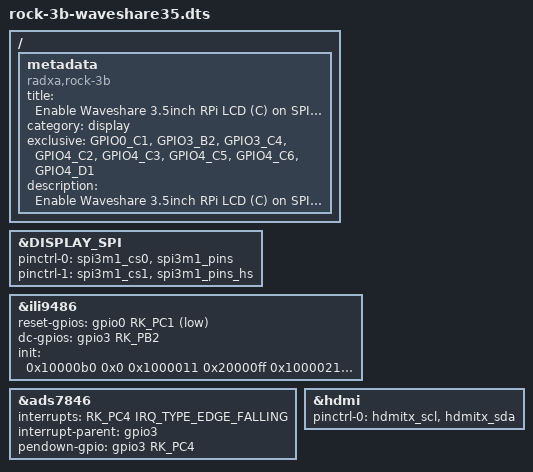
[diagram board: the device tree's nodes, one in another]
#define DISPLAY_SPI spi3
#include "waveshare35-lcd.dtsi"

/ {
	metadata {
		title = "Enable Waveshare 3.5inch RPi LCD (C) on SPI3-M1";
		compatible = "radxa,rock-3b";
		category = "display";
		exclusive = "GPIO0_C1", "GPIO3_B2", "GPIO3_C4", "GPIO4_C2", "GPIO4_C3", "GPIO4_C5",  "GPIO4_C6", "GPIO4_D1";
		description = "Enable Waveshare 3.5inch RPi LCD (C) on SPI3-M1.
HDMI CEC function will be turned off when this overlay is enabled.";
	};
};

&DISPLAY_SPI {
	pinctrl-names = "default", "high_speed";
	pinctrl-0 = <&spi3m1_cs0 &spi3m1_pins>;
	pinctrl-1 = <&spi3m1_cs1 &spi3m1_pins_hs>;
};

&ili9486 {
	reset-gpios = <&gpio0 RK_PC1 GPIO_ACTIVE_LOW>;
	dc-gpios = <&gpio3 RK_PB2 GPIO_ACTIVE_HIGH>;
	init = <0x10000b0 0x0
			0x1000011
			0x20000ff
			0x1000021
			0x100003a 0x55
			0x10000c2 0x33
			0x10000c5 0x0 0x1e 0x80
			0x1000036 0x28
			0x10000b1 0xb0
			0x10000e0 0x0 0x13 0x18 0x4 0xf 0x6 0x3a 0x56 0x4d 0x3 0xa 0x6 0x30 0x3e 0xf
			0x10000e1 0x0 0x13 0x18 0x1 0x11 0x6 0x38 0x34 0x4d 0x6 0xd 0xb 0x31 0x37 0xf
			0x1000011
			0x20000ff
			0x1000029>;
};

&ads7846 {
	interrupts = <RK_PC4 IRQ_TYPE_EDGE_FALLING>;
	interrupt-parent = <&gpio3>;
	pendown-gpio = <&gpio3 RK_PC4 GPIO_ACTIVE_HIGH>;
};

&hdmi {
	pinctrl-names = "default";
	pinctrl-0 = <&hdmitx_scl &hdmitx_sda>; 
};
